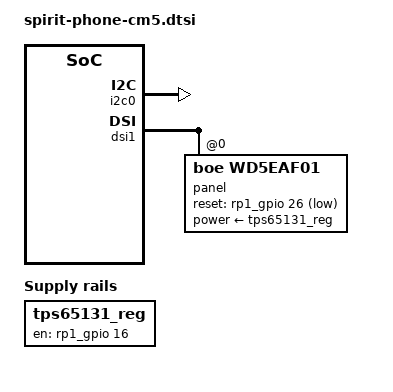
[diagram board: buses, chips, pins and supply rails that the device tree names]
// SPDX-License-Identifier: GPL-2.0
&i2c0 {
	status = "okay";

	/* PMIC */
	spirit_pmic: spirit-pmic@48 {
		compatible = "ti,tps65023";
		reg = <0x48>;
		status = "disabled";

		regulators {
			VDCDC1 {
				regulator-name = "3v3a";
				regulator-boot-on;
				regulator-min-microvolt = <3300000>;
				regulator-max-microvolt = <3300000>;
			};

			VDCDC2 {
				regulator-name = "1v8";
				regulator-always-on;
				regulator-min-microvolt = <1800000>;
				regulator-max-microvolt = <1800000>;
			};

			VDCDC3 {
				regulator-name = "3v3b";
				regulator-always-on;
				regulator-min-microvolt = <3300000>;
				regulator-max-microvolt = <3300000>;
			};
		};
	};
};

/ {
	tps65131_reg: tps65131-regulator {
		compatible = "regulator-fixed";
		regulator-name = "tps65131-en";
		gpios = <&rp1_gpio 16 GPIO_ACTIVE_HIGH>;
		enable-active-high;
		regulator-boot-on;
	};
};

&dsi1 {
	status = "okay";

	panel@0 {
		reg = <0>;
		compatible = "boe,wd5eaf01";

		reset-gpios = <&rp1_gpio 26 GPIO_ACTIVE_LOW>;
		power-supply = <&tps65131_reg>;
	};
};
